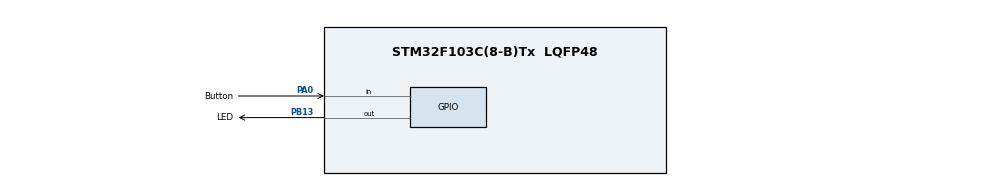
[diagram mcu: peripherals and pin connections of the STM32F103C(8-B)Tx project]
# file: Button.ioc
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Mcu.Family=STM32F1
Mcu.Name=STM32F103C(8-B)Tx
Mcu.Package=LQFP48
NVIC.PriorityGroup=NVIC_PRIORITYGROUP_4
PA0-WKUP.GPIO_Label=Button
PA0-WKUP.GPIO_PuPd=GPIO_PULLDOWN
PA0-WKUP.Signal=GPIO_Input
PA13.Mode=Serial_Wire
PA13.Signal=SYS_JTMS-SWDIO
PA14.Mode=Serial_Wire
PA14.Signal=SYS_JTCK-SWCLK
PB13.GPIO_Label=LED
PB13.Signal=GPIO_Output
ProjectManager.HeapSize=0x200
ProjectManager.StackSize=0x400
ProjectManager.TargetToolchain=MDK-ARM V5
RCC.APB1Freq_Value=8000000
RCC.APB2Freq_Value=8000000
board=Button

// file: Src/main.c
/* USER CODE BEGIN Header */
/**
  ******************************************************************************
  * @file           : main.c
  * @brief          : Main program body
  ******************************************************************************
  * @attention
  *
  * <h2><center>&copy; Copyright (c) 2020 STMicroelectronics.
  * All rights reserved.</center></h2>
  *
  * This software component is licensed by ST under BSD 3-Clause license,
  * the "License"; You may not use this file except in compliance with the
  * License. You may obtain a copy of the License at:
  *                        opensource.org/licenses/BSD-3-Clause
  *
  ******************************************************************************
  */
/* USER CODE END Header */

#include "main.h"

/* USER CODE BEGIN PV */
/* Private variables ---------------------------------------------------------*/

/* USER CODE END PV */

void SystemClock_Config(void);
static void MX_GPIO_Init(void);
/* USER CODE BEGIN PFP */
/* Private function prototypes -----------------------------------------------*/

/* USER CODE END PFP */

int main(void)
{

  /* MCU Configuration--------------------------------------------------------*/

  /* Reset of all peripherals, Initializes the Flash interface and the Systick. */
  HAL_Init();

  /* Configure the system clock */
  SystemClock_Config();

  /* Initialize all configured peripherals */
  MX_GPIO_Init();

  /* Infinite loop */
  while (1)
  {

    /* USER CODE BEGIN 3 */
		if(HAL_GPIO_ReadPin(GPIOA, GPIO_PIN_0)){	//Kiem tra xem co an nut hay khong
			HAL_GPIO_WritePin(GPIOB, GPIO_PIN_13, GPIO_PIN_SET);	//Neu co thi bat LED
		}
		else
		{
			HAL_GPIO_WritePin(GPIOB, GPIO_PIN_13, GPIO_PIN_RESET);	//Neu khong an nut thi LED tat
		}
  }
  /* USER CODE END 3 */
}

void SystemClock_Config(void)
{
  RCC_OscInitTypeDef RCC_OscInitStruct = {0};
  RCC_ClkInitTypeDef RCC_ClkInitStruct = {0};

  /** Initializes the CPU, AHB and APB busses clocks
  */
  RCC_OscInitStruct.OscillatorType = RCC_OSCILLATORTYPE_HSI;
  RCC_OscInitStruct.HSIState = RCC_HSI_ON;
  RCC_OscInitStruct.HSICalibrationValue = RCC_HSICALIBRATION_DEFAULT;
  RCC_OscInitStruct.PLL.PLLState = RCC_PLL_NONE;
  if (HAL_RCC_OscConfig(&RCC_OscInitStruct) != HAL_OK)
  {
    Error_Handler();
  }
  /** Initializes the CPU, AHB and APB busses clocks
  */
  RCC_ClkInitStruct.ClockType = RCC_CLOCKTYPE_HCLK|RCC_CLOCKTYPE_SYSCLK
                              |RCC_CLOCKTYPE_PCLK1|RCC_CLOCKTYPE_PCLK2;
  RCC_ClkInitStruct.SYSCLKSource = RCC_SYSCLKSOURCE_HSI;
  RCC_ClkInitStruct.AHBCLKDivider = RCC_SYSCLK_DIV1;
  RCC_ClkInitStruct.APB1CLKDivider = RCC_HCLK_DIV1;
  RCC_ClkInitStruct.APB2CLKDivider = RCC_HCLK_DIV1;

  if (HAL_RCC_ClockConfig(&RCC_ClkInitStruct, FLASH_LATENCY_0) != HAL_OK)
  {
    Error_Handler();
  }
}

static void MX_GPIO_Init(void)
{
  GPIO_InitTypeDef GPIO_InitStruct = {0};

  /* GPIO Ports Clock Enable */
  __HAL_RCC_GPIOA_CLK_ENABLE();
  __HAL_RCC_GPIOB_CLK_ENABLE();

  /*Configure GPIO pin Output Level */
  HAL_GPIO_WritePin(LED_GPIO_Port, LED_Pin, GPIO_PIN_RESET);

  /*Configure GPIO pin : Button_Pin */
  GPIO_InitStruct.Pin = Button_Pin;
  GPIO_InitStruct.Mode = GPIO_MODE_INPUT;
  GPIO_InitStruct.Pull = GPIO_PULLDOWN;
  HAL_GPIO_Init(Button_GPIO_Port, &GPIO_InitStruct);

  /*Configure GPIO pin : LED_Pin */
  GPIO_InitStruct.Pin = LED_Pin;
  GPIO_InitStruct.Mode = GPIO_MODE_OUTPUT_PP;
  GPIO_InitStruct.Pull = GPIO_NOPULL;
  GPIO_InitStruct.Speed = GPIO_SPEED_FREQ_LOW;
  HAL_GPIO_Init(LED_GPIO_Port, &GPIO_InitStruct);

}

void Error_Handler(void)
{
}

/************************ (C) COPYRIGHT STMicroelectronics *****END OF FILE****/
